# jbr_MDR1986VE1T register map
Registers are 32-bit, access not given, no defined reset value unless marked. A register's access mark holds for its fields unless they carry their own. Addresses are absolute; registers are grouped by the start of their names; [hi:lo] are bit positions; {n}, {i} and the like mark numbered series.

## ADC1
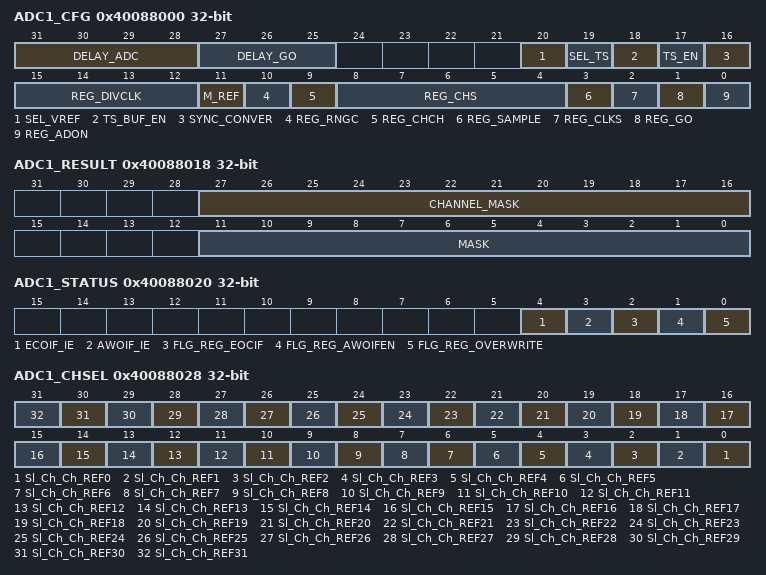
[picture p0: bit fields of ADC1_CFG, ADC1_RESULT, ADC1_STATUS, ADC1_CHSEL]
0x40088000 ADC1_CFG
  [31:28] DELAY_ADC, [27:25] DELAY_GO, [20] SEL_VREF, [19] SEL_TS, [18] TS_BUF_EN, [17] TS_EN, [16] SYNC_CONVER, [15:12] REG_DIVCLK, [11] M_REF, [10] REG_RNGC, [9] REG_CHCH, [8:4] REG_CHS, [3] REG_SAMPLE, [2] REG_CLKS, [1] REG_GO, [0] REG_ADON
0x40088008 ADC1_H_LEVEL
0x40088010 ADC1_L_LEVEL
0x40088018 ADC1_RESULT
  [27:16] CHANNEL_MASK, [11:0] MASK
0x40088020 ADC1_STATUS
  [4] ECOIF_IE, [3] AWOIF_IE, [2] FLG_REG_EOCIF, [1] FLG_REG_AWOIFEN, [0] FLG_REG_OVERWRITE
0x40088028 ADC1_CHSEL
  [n] Sl_Ch_Ch_REF{n} (n=0..31)
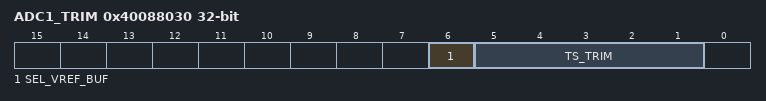
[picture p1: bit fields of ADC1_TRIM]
0x40088030 ADC1_TRIM
  [6] SEL_VREF_BUF, [5:1] TS_TRIM

## GPIOA
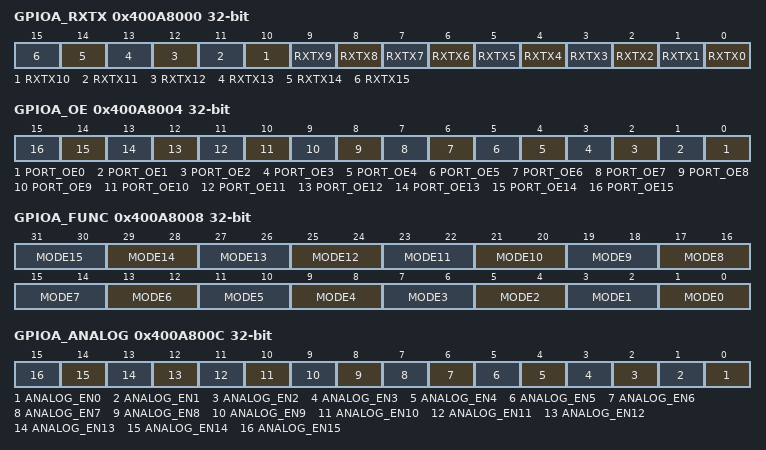
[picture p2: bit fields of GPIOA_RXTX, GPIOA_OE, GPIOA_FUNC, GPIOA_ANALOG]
0x400A8000 GPIOA_RXTX
  [n] RXTX{n} (n=0..15)
0x400A8004 GPIOA_OE
  [n] PORT_OE{n} (n=0..15)
0x400A8008 GPIOA_FUNC
  [2n+1:2n] MODE{n} (n=0..15)
0x400A800C GPIOA_ANALOG
  [n] ANALOG_EN{n} (n=0..15)
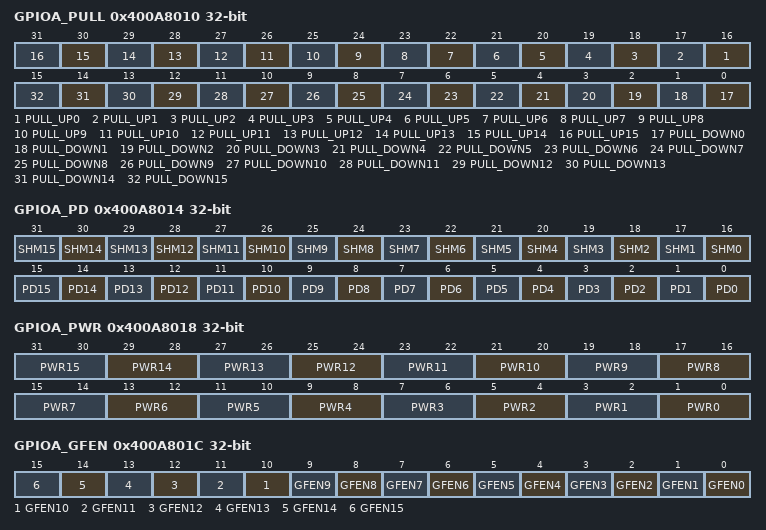
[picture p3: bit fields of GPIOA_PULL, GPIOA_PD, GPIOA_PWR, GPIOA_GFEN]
0x400A8010 GPIOA_PULL
  [n+16] PULL_UP{n} (n=0..15), [n] PULL_DOWN{n} (n=0..15)
0x400A8014 GPIOA_PD
  [n+16] SHM{n} (n=0..15), [n] PD{n} (n=0..15)
0x400A8018 GPIOA_PWR
  [2n+1:2n] PWR{n} (n=0..15)
0x400A801C GPIOA_GFEN
  [n] GFEN{n} (n=0..15)
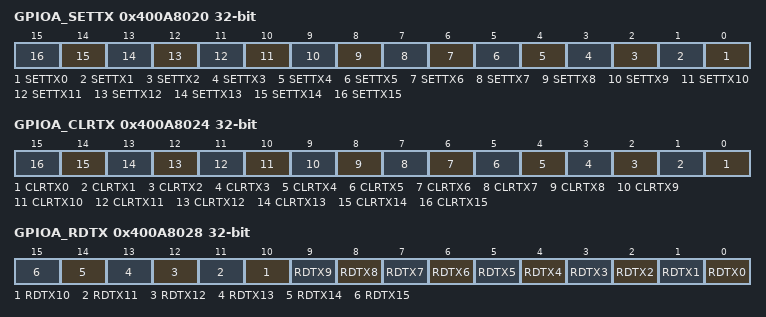
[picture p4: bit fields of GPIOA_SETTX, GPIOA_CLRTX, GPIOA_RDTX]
0x400A8020 GPIOA_SETTX
  [n] SETTX{n} (n=0..15)
0x400A8024 GPIOA_CLRTX
  [n] CLRTX{n} (n=0..15)
0x400A8028 GPIOA_RDTX
  [n] RDTX{n} (n=0..15)

## GPIOB
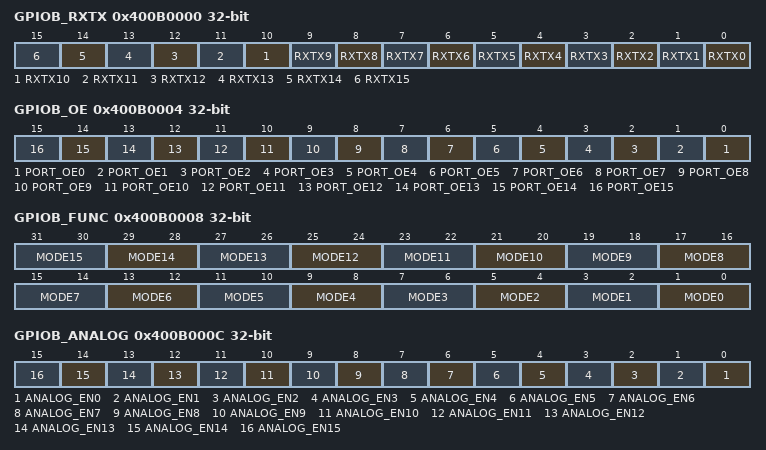
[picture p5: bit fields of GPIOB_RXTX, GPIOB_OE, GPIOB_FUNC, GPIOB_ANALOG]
0x400B0000 GPIOB_RXTX
  [n] RXTX{n} (n=0..15)
0x400B0004 GPIOB_OE
  [n] PORT_OE{n} (n=0..15)
0x400B0008 GPIOB_FUNC
  [2n+1:2n] MODE{n} (n=0..15)
0x400B000C GPIOB_ANALOG
  [n] ANALOG_EN{n} (n=0..15)
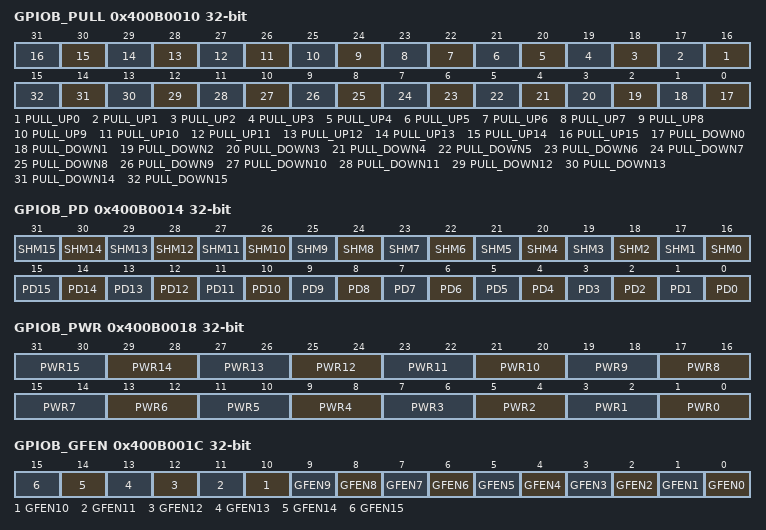
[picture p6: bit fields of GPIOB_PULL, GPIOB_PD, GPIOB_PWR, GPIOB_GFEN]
0x400B0010 GPIOB_PULL
  [n+16] PULL_UP{n} (n=0..15), [n] PULL_DOWN{n} (n=0..15)
0x400B0014 GPIOB_PD
  [n+16] SHM{n} (n=0..15), [n] PD{n} (n=0..15)
0x400B0018 GPIOB_PWR
  [2n+1:2n] PWR{n} (n=0..15)
0x400B001C GPIOB_GFEN
  [n] GFEN{n} (n=0..15)
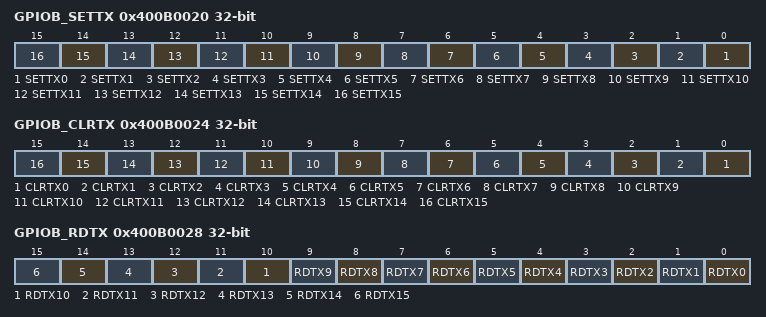
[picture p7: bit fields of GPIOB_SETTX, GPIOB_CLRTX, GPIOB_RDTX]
0x400B0020 GPIOB_SETTX
  [n] SETTX{n} (n=0..15)
0x400B0024 GPIOB_CLRTX
  [n] CLRTX{n} (n=0..15)
0x400B0028 GPIOB_RDTX
  [n] RDTX{n} (n=0..15)

## GPIOC
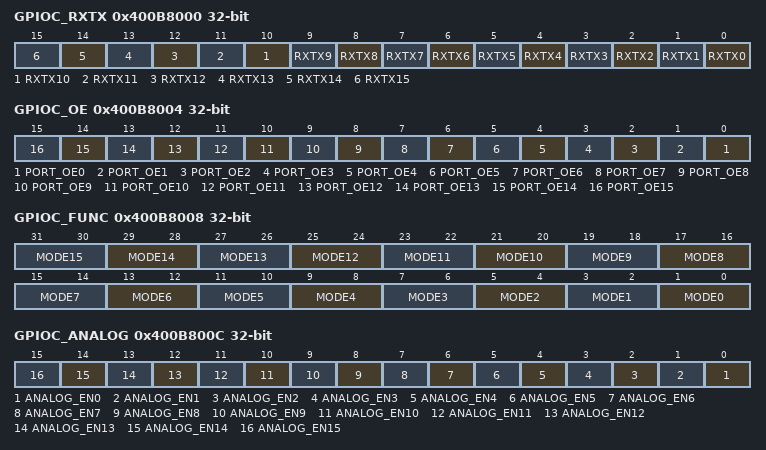
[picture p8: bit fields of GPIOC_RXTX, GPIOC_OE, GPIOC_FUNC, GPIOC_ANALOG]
0x400B8000 GPIOC_RXTX
  [n] RXTX{n} (n=0..15)
0x400B8004 GPIOC_OE
  [n] PORT_OE{n} (n=0..15)
0x400B8008 GPIOC_FUNC
  [2n+1:2n] MODE{n} (n=0..15)
0x400B800C GPIOC_ANALOG
  [n] ANALOG_EN{n} (n=0..15)
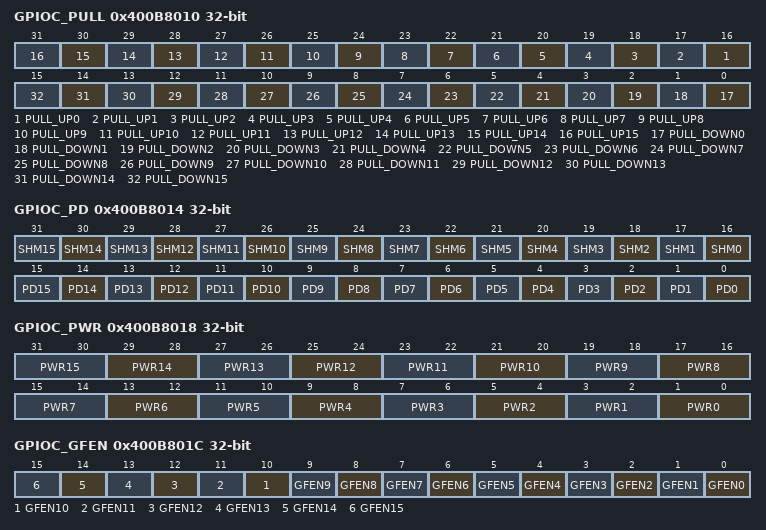
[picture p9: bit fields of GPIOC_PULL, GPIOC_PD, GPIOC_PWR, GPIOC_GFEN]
0x400B8010 GPIOC_PULL
  [n+16] PULL_UP{n} (n=0..15), [n] PULL_DOWN{n} (n=0..15)
0x400B8014 GPIOC_PD
  [n+16] SHM{n} (n=0..15), [n] PD{n} (n=0..15)
0x400B8018 GPIOC_PWR
  [2n+1:2n] PWR{n} (n=0..15)
0x400B801C GPIOC_GFEN
  [n] GFEN{n} (n=0..15)
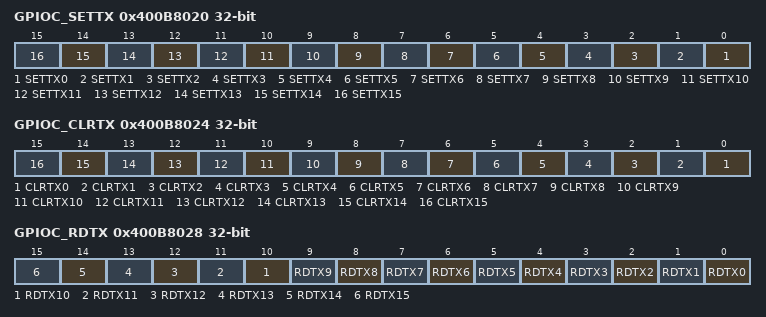
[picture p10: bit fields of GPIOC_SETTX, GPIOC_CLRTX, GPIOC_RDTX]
0x400B8020 GPIOC_SETTX
  [n] SETTX{n} (n=0..15)
0x400B8024 GPIOC_CLRTX
  [n] CLRTX{n} (n=0..15)
0x400B8028 GPIOC_RDTX
  [n] RDTX{n} (n=0..15)

## GPIOD
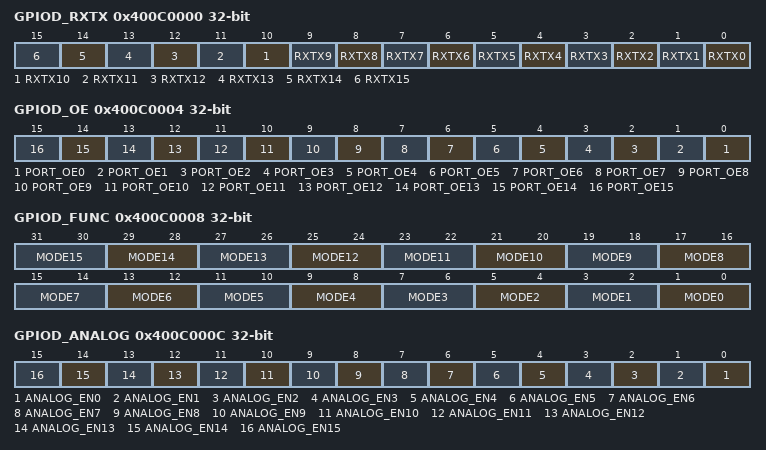
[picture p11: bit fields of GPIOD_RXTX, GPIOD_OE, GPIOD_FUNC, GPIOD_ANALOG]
0x400C0000 GPIOD_RXTX
  [n] RXTX{n} (n=0..15)
0x400C0004 GPIOD_OE
  [n] PORT_OE{n} (n=0..15)
0x400C0008 GPIOD_FUNC
  [2n+1:2n] MODE{n} (n=0..15)
0x400C000C GPIOD_ANALOG
  [n] ANALOG_EN{n} (n=0..15)
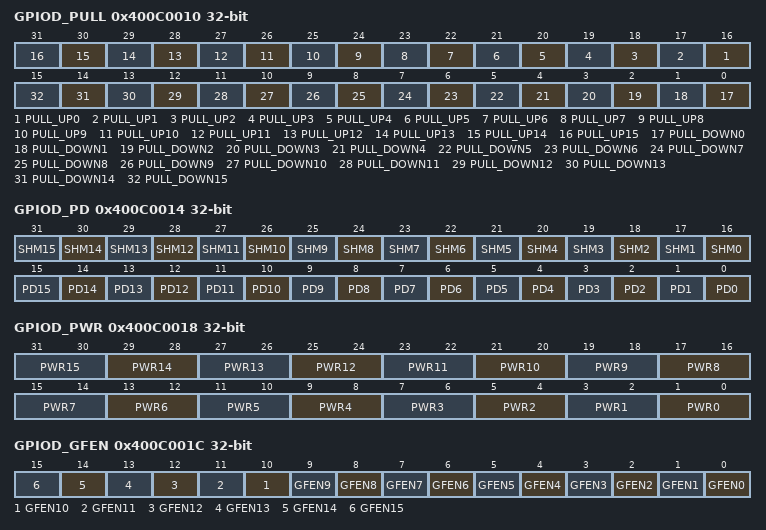
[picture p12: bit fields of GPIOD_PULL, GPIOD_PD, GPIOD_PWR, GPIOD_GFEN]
0x400C0010 GPIOD_PULL
  [n+16] PULL_UP{n} (n=0..15), [n] PULL_DOWN{n} (n=0..15)
0x400C0014 GPIOD_PD
  [n+16] SHM{n} (n=0..15), [n] PD{n} (n=0..15)
0x400C0018 GPIOD_PWR
  [2n+1:2n] PWR{n} (n=0..15)
0x400C001C GPIOD_GFEN
  [n] GFEN{n} (n=0..15)
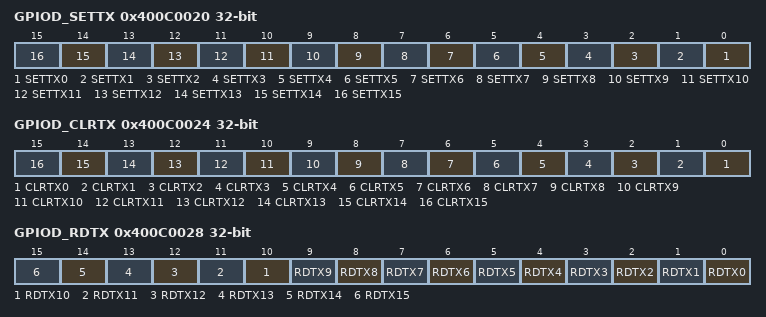
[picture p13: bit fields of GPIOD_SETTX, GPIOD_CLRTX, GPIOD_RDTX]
0x400C0020 GPIOD_SETTX
  [n] SETTX{n} (n=0..15)
0x400C0024 GPIOD_CLRTX
  [n] CLRTX{n} (n=0..15)
0x400C0028 GPIOD_RDTX
  [n] RDTX{n} (n=0..15)

## GPIOE
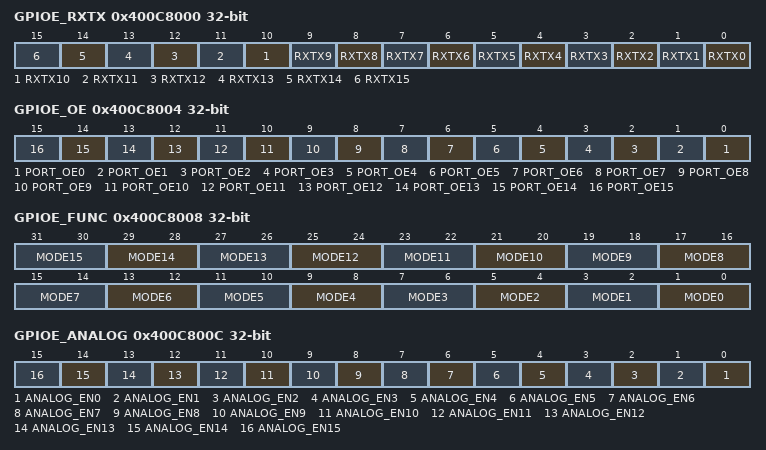
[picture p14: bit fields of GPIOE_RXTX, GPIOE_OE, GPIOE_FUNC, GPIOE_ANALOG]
0x400C8000 GPIOE_RXTX
  [n] RXTX{n} (n=0..15)
0x400C8004 GPIOE_OE
  [n] PORT_OE{n} (n=0..15)
0x400C8008 GPIOE_FUNC
  [2n+1:2n] MODE{n} (n=0..15)
0x400C800C GPIOE_ANALOG
  [n] ANALOG_EN{n} (n=0..15)
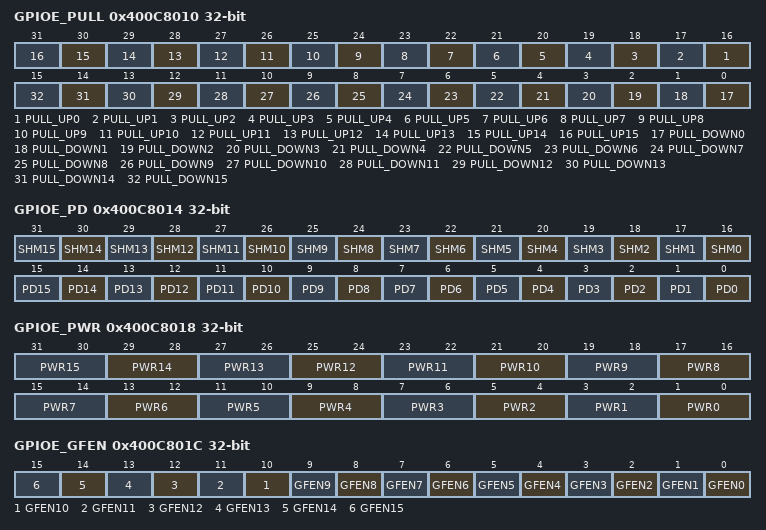
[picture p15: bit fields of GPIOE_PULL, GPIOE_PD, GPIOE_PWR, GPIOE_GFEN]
0x400C8010 GPIOE_PULL
  [n+16] PULL_UP{n} (n=0..15), [n] PULL_DOWN{n} (n=0..15)
0x400C8014 GPIOE_PD
  [n+16] SHM{n} (n=0..15), [n] PD{n} (n=0..15)
0x400C8018 GPIOE_PWR
  [2n+1:2n] PWR{n} (n=0..15)
0x400C801C GPIOE_GFEN
  [n] GFEN{n} (n=0..15)
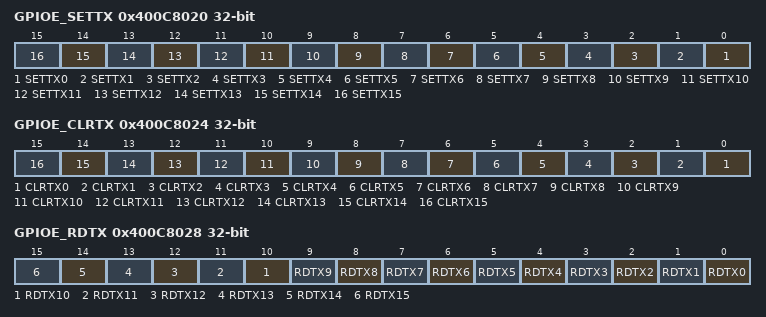
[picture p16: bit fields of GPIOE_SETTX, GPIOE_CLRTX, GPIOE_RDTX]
0x400C8020 GPIOE_SETTX
  [n] SETTX{n} (n=0..15)
0x400C8024 GPIOE_CLRTX
  [n] CLRTX{n} (n=0..15)
0x400C8028 GPIOE_RDTX
  [n] RDTX{n} (n=0..15)
